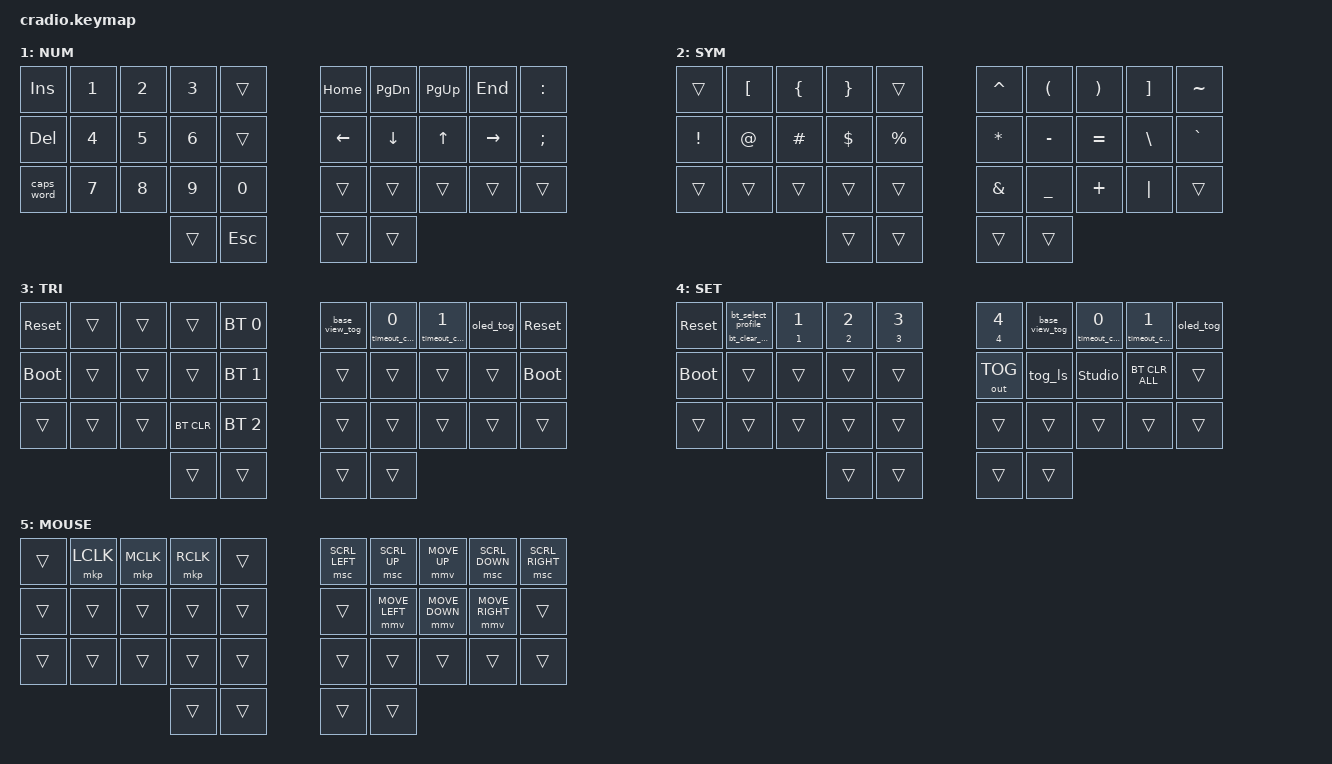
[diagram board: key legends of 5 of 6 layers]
// Copyright (c) 2022 The ZMK Contributors
// SPDX-License-Identifier: MIT

#include <behaviors.dtsi>
#include <dt-bindings/zmk/keys.h>
#include <dt-bindings/zmk/bt.h>
#include <dt-bindings/zmk/outputs.h>
#include <dt-bindings/zmk/pointing.h>
#include <dt-bindings/zmk/layout_shift.h>
#include <layout_shift_kp_override.dtsi>
#include "studio_runtime_layers.dtsi"

/* Adjusted Cradio pin arrangement */
&kscan0 {
    input-gpios
    = <&pro_micro  6 (GPIO_ACTIVE_LOW | GPIO_PULL_UP)>
    , <&pro_micro 18 (GPIO_ACTIVE_LOW | GPIO_PULL_UP)>
    , <&pro_micro 19 (GPIO_ACTIVE_LOW | GPIO_PULL_UP)>
    , <&pro_micro 20 (GPIO_ACTIVE_LOW | GPIO_PULL_UP)>
    , <&pro_micro 21 (GPIO_ACTIVE_LOW | GPIO_PULL_UP)>
    , <&pro_micro 15 (GPIO_ACTIVE_LOW | GPIO_PULL_UP)>
    , <&pro_micro 14 (GPIO_ACTIVE_LOW | GPIO_PULL_UP)>
    , <&pro_micro 16 (GPIO_ACTIVE_LOW | GPIO_PULL_UP)>
    , <&pro_micro 10 (GPIO_ACTIVE_LOW | GPIO_PULL_UP)>
    , <&pro_micro  1 (GPIO_ACTIVE_LOW | GPIO_PULL_UP)>
    , <&pro_micro  2 (GPIO_ACTIVE_LOW | GPIO_PULL_UP)>
    , <&pro_micro  3 (GPIO_ACTIVE_LOW | GPIO_PULL_UP)>
    , <&pro_micro  4 (GPIO_ACTIVE_LOW | GPIO_PULL_UP)>
    , <&pro_micro  5 (GPIO_ACTIVE_LOW | GPIO_PULL_UP)>
    , <&pro_micro  7 (GPIO_ACTIVE_LOW | GPIO_PULL_UP)>
    , <&pro_micro  9 (GPIO_ACTIVE_LOW | GPIO_PULL_UP)>
    , <&pro_micro  8 (GPIO_ACTIVE_LOW | GPIO_PULL_UP)>
    ;
};

// Home row mods macro
// Windows default: GUI/Windows key sits on the outer home-row mod; Alt sits closer to the index finger.
#define HRML(k1,k2,k3,k4) &ht LSHFT k1  &ht LGUI k2  &ht LCTRL k3  &ht LALT k4
#define HRMR(k1,k2,k3,k4) &ht RALT k1  &ht RCTRL k2  &ht RGUI k3  &ht RSHFT k4

/ {
    macros {
        // Tap selects a host profile; a 3-second hold clears it and opens pairing.
        bt_select_profile: bt_select_profile {
            compatible = "zmk,behavior-macro-one-param";
            #binding-cells = <1>;
            bindings =
                <&macro_param_1to2>,
                <&bt BT_SEL MACRO_PLACEHOLDER>;
        };

        bt_clear_profile: bt_clear_profile {
            compatible = "zmk,behavior-macro-one-param";
            #binding-cells = <1>;
            wait-ms = <20>;
            bindings =
                <&macro_param_1to2>,
                <&bt BT_SEL MACRO_PLACEHOLDER>,
                <&bt BT_CLR>;
        };
    };

    // Layout shift OFF = Windows (default); ON = Mac (GUI/Windows and Alt/Option swap).
    layout_shift_map_gui_alt: layout_shift_map_gui_alt {
        compatible = "zmk,layout-shift-map";
        mappings = <
            LGUI LALT LAYOUT_SHIFT_OPTIONAL_ALL
            LALT LGUI LAYOUT_SHIFT_OPTIONAL_ALL
            RGUI RALT LAYOUT_SHIFT_OPTIONAL_ALL
            RALT RGUI LAYOUT_SHIFT_OPTIONAL_ALL
        >;
    };

    behaviors {
        bt_profile: bt_profile {
            compatible = "zmk,behavior-hold-tap";
            #binding-cells = <2>;
            flavor = "tap-preferred";
            tapping-term-ms = <3000>;
            bindings = <&bt_clear_profile>, <&bt_select_profile>;
            hold-trigger-key-positions = <
                0xffffffff 0xffffffff 0xffffffff 0xffffffff
                0xffffffff 0xffffffff 0xffffffff 0xffffffff
                0xffffffff 0xffffffff 0xffffffff 0xffffffff
            >;
            display-name = "Bluetooth Profile";
        };
        ht: hold_tap {
            compatible = "zmk,behavior-hold-tap";
            #binding-cells = <2>;
            flavor = "tap-preferred";
            tapping-term-ms = <220>;
            quick-tap-ms = <150>;
            require-prior-idle-ms = <100>;
            bindings = <&kp>, <&kp>;
        };

        // Hana-style dongle/display controls. These are assigned only to
        // previously transparent positions on Sweep's existing tri-layer.
        oled_tog: oled_toggle {
            compatible = "zmk,behavior-oled-toggle";
            #binding-cells = <0>;
            display-name = "OLED Toggle";
        };

        base_view_tog: base_view_toggle {
            compatible = "zmk,behavior-base-view-toggle";
            #binding-cells = <0>;
            display-name = "BASE View Cycle";
        };

        timeout_cycle: timeout_cycle {
            compatible = "zmk,behavior-timeout-cycle";
            #binding-cells = <1>;
            display-name = "Timeout Cycle";
        };
    };

    conditional_layers {
        compatible = "zmk,conditional-layers";
        tri_layer {
            if-layers = <1 2>;
            then-layer = <3>;
        };
    };

    keymap {
        compatible = "zmk,keymap";
        default_layer {
            display-name = "BASE";
            bindings = <
        //╭──────────┬──────────┬──────────┬──────────┬──────────╮   ╭──────────┬──────────┬──────────┬──────────┬──────────╮
        //│  Q       │  W       │  E       │  R       │  T       │   │  Y       │  U       │  I       │  O       │  P       │
            &kp Q      &kp W      &kp E      &kp R      &kp T          &kp Y      &kp U      &kp I      &kp O      &kp P
        //├──────────┼──────────┼──────────┼──────────┼──────────┤   ├──────────┼──────────┼──────────┼──────────┼──────────┤
        //│  A       │  S       │  D       │  F       │  G       │   │  H       │  J       │  K       │  L       │ ' "      │
            HRML(A,        S,         D,         F)     &kp G          &kp H      HRMR(J,        K,         L,        SQT)
        //├──────────┼──────────┼──────────┼──────────┼──────────┤   ├──────────┼──────────┼──────────┼──────────┼──────────┤
        //│  Z       │  X       │  C       │  V       │  B       │   │  N       │  M       │ , <      │ . >      │ / ?      │
            &kp Z      &kp X      &kp C      &kp V      &kp B          &kp N      &kp M      &kp COMMA  &kp DOT    &kp FSLH
        //╰──────────┴──────────┴──────────┼──────────┼──────────┤   ├──────────┼──────────┼──────────┴──────────┴──────────╯
                                            &lt 2 TAB   &lt 4 ENTER     &lt 5 SPACE  &lt 1 BSPC
        //                                 ╰──────────┴──────────╯   ╰──────────┴──────────╯
            >;
        };

        right_layer {
            display-name = "NUM";
            bindings = <
        //╭──────────┬──────────┬──────────┬──────────┬──────────╮   ╭──────────┬──────────┬──────────┬──────────┬──────────╮
        //│ INSERT   │  1       │  2       │  3       │          │   │ HOME     │ PAGE DN  │ PAGE UP  │ END      │  :       │
            &kp INS    &kp N1     &kp N2     &kp N3     &trans         &kp HOME   &kp PG_DN  &kp PG_UP  &kp END    &kp COLON
        //├──────────┼──────────┼──────────┼──────────┼──────────┤   ├──────────┼──────────┼──────────┼──────────┼──────────┤
        //│ DELETE   │  4       │  5       │  6       │          │   │ LEFT     │ DOWN     │ UP       │ RIGHT    │  ;       │
            &kp DEL    &kp N4     &kp N5     &kp N6     &trans         &kp LEFT   &kp DOWN   &kp UP   &kp RIGHT   &kp SEMI
        //├──────────┼──────────┼──────────┼──────────┼──────────┤   ├──────────┼──────────┼──────────┼──────────┼──────────┤
        //│ CAPS     │  7       │  8       │  9       │  0       │   │          │          │          │          │          │
           &caps_word  &kp N7     &kp N8     &kp N9     &kp N0         &trans     &trans     &trans     &trans     &trans
        //╰──────────┴──────────┴──────────┼──────────┼──────────┤   ├──────────┼──────────┼──────────┴──────────┴──────────╯
                                             &trans     &kp ESC        &trans     &trans
        //                                 ╰──────────┴──────────╯   ╰──────────┴──────────╯
            >;
        };

        left_layer {
            display-name = "SYM";
            bindings = <
        //╭──────────┬──────────┬──────────┬──────────┬──────────╮   ╭──────────┬──────────┬──────────┬──────────┬──────────╮
        //│          │  [       │  {       │  }       │          │   │  ^       │  (       │  )       │  ]       │  ~       │
            &trans     &kp LBKT   &kp LBRC   &kp RBRC   &trans         &kp CARET  &kp LPAR   &kp RPAR   &kp RBKT   &kp TILDE
        //├──────────┼──────────┼──────────┼──────────┼──────────┤   ├──────────┼──────────┼──────────┼──────────┼──────────┤
        //│  !       │  @       │  #       │  $       │  %       │   │  *       │  -       │  =       │  \       │  `       │
            &kp EXCL   &kp AT     &kp HASH   &kp DLLR   &kp PRCNT      &kp ASTRK  &kp MINUS  &kp EQUAL  &kp BSLH   &kp GRAVE
        //├──────────┼──────────┼──────────┼──────────┼──────────┤   ├──────────┼──────────┼──────────┼──────────┼──────────┤
        //│          │          │          │          │          │   │  &       │  _       │  +       │  │       │          │
            &trans     &trans     &trans     &trans     &trans         &kp AMPS   &kp UNDER  &kp PLUS   &kp PIPE   &trans
        //╰──────────┴──────────┴──────────┼──────────┼──────────┤   ├──────────┼──────────┼──────────┴──────────┴──────────╯
                                             &trans     &trans         &trans     &trans
        //                                 ╰──────────┴──────────╯   ╰──────────┴──────────╯
            >;
        };

        tri_layer {
            display-name = "TRI";
            bindings = <
        //╭──────────┬──────────┬──────────┬──────────┬──────────╮   ╭──────────┬──────────┬──────────┬──────────┬──────────╮
        //│ RESET    │          │          │          │PROFILE 0 │   │          │          │          │          │  RESET   │
           &sys_reset  &trans     &trans     &trans    &bt BT_SEL 0    &base_view_tog  &timeout_cycle 0  &timeout_cycle 1  &oled_tog  &sys_reset
        //├──────────┼──────────┼──────────┼──────────┼──────────┤   ├──────────┼──────────┼──────────┼──────────┼──────────┤
        //│BOOTLOADER│          │          │          │PROFILE 1 │   │          │          │          │          │BOOTLOADER│
          &bootloader  &trans     &trans     &trans    &bt BT_SEL 1    &trans     &trans     &trans     &trans    &bootloader
        //├──────────┼──────────┼──────────┼──────────┼──────────┤   ├──────────┼──────────┼──────────┼──────────┼──────────┤
        //│          │          │          │ CLEAR BT │PROFILE 2 │   │          │          │          │          │          │
            &trans     &trans     &trans    &bt BT_CLR &bt BT_SEL 2    &trans     &trans     &trans     &trans     &trans
        //╰──────────┴──────────┴──────────┼──────────┼──────────┤   ├──────────┼──────────┼──────────┴──────────┴──────────╯
                                             &trans     &trans         &trans     &trans
        //                                 ╰──────────┴──────────╯   ╰──────────┴──────────╯
            >;
        };

        // SET is a dedicated settings layer, held with the left Enter thumb.
        // Every row remains within Sweep's five-column-per-half layout.
        set_layer {
            display-name = "SET";
            bindings = <
                &sys_reset &bt_profile 0 0 &bt_profile 1 1 &bt_profile 2 2 &bt_profile 3 3
                &bt_profile 4 4 &base_view_tog &timeout_cycle 0 &timeout_cycle 1 &oled_tog

                &bootloader &trans &trans &trans &trans
                &out OUT_TOG &tog_ls &studio_unlock &bt BT_CLR_ALL &trans

                &trans &trans &trans &trans &trans
                &trans &trans &trans &trans &trans

                &trans &trans &trans &trans
            >;
        };

        // MOUSE is a dedicated mouse/scroll layer, held with the right Space thumb.
        mouse_layer {
            display-name = "MOUSE";
            bindings = <
                &trans &mkp LCLK &mkp MCLK &mkp RCLK &trans
                &msc SCRL_LEFT &msc SCRL_UP &mmv MOVE_UP &msc SCRL_DOWN &msc SCRL_RIGHT

                &trans &trans &trans &trans &trans
                &trans &mmv MOVE_LEFT &mmv MOVE_DOWN &mmv MOVE_RIGHT &trans

                &trans &trans &trans &trans &trans
                &trans &trans &trans &trans &trans

                &trans &trans &trans &trans
            >;
        };

        ZMK_STUDIO_RUNTIME_LAYER_SLOTS_4
    };
};

&tog_ls {
    layout-maps = <&layout_shift_map_gui_alt>;
};
